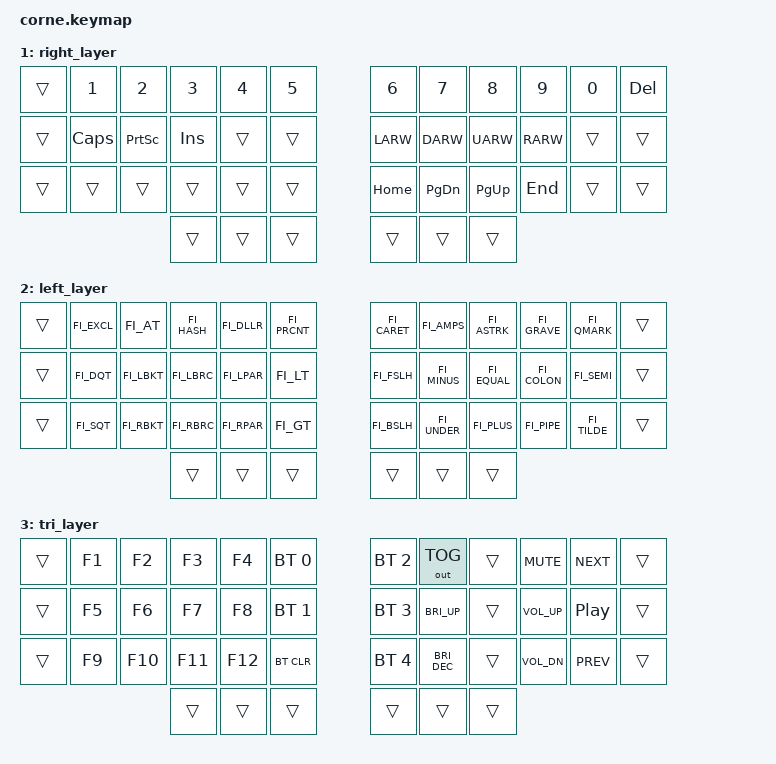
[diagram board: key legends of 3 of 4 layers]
#include <behaviors.dtsi>
#include <dt-bindings/zmk/keys.h>
#include <dt-bindings/zmk/bt.h>
#include <dt-bindings/zmk/outputs.h>
#include <locale/keys_fi.h>

// Home row mods
#define HRML(k2,k3,k4) &ht LALT k2  &ht LCTRL k3  &ht LGUI k4

// Right hand uses left-side modifier keycodes intentionally.
// On Nordic/Finnish layouts, RALT behaves as AltGr, so using LALT here
// gives normal Alt behavior on the physical right-hand home-row key.
#define HRMR(k1,k2,k3) &ht LGUI k1  &ht LCTRL k2  &ht LALT k3

#define DEF 0
#define RIG 1
#define LEF 2
#define TRI 3

/ {
    behaviors {
        ht: hold_tap {
            label = "hold_tap";
            compatible = "zmk,behavior-hold-tap";
            #binding-cells = <2>;
            flavor = "tap-preferred";
            tapping-term-ms = <220>;
            quick-tap-ms = <150>;
            global-quick-tap;
            bindings = <&kp>, <&kp>;
        };
    };

    conditional_layers {
        compatible = "zmk,conditional-layers";

        tri_layer {
            if-layers = <RIG LEF>;
            then-layer = <TRI>;
        };
    };

    keymap {
        compatible = "zmk,keymap";

        default_layer {
            bindings = <
        //╭──────────┬──────────┬──────────┬──────────┬──────────┬──────────╮   ╭──────────┬──────────┬──────────┬──────────┬──────────┬──────────╮
        //│  ESC     │  Q       │  W       │  E       │  R       │  T       │   │  Y       │  U       │  I       │  O       │  P       │ BACKSPC  │
            &kp ESC    &kp Q      &kp W      &kp E      &kp R      &kp T          &kp Y      &kp U      &kp I      &kp O      &kp P      &kp BSPC

        //├──────────┼──────────┼──────────┼──────────┼──────────┼──────────┤   ├──────────┼──────────┼──────────┼──────────┼──────────┼──────────┤
        //│  TAB     │  A       │  S/ALT   │  D/CTRL  │  F/GUI   │  G       │   │  H       │  J/GUI   │  K/CTRL  │  L/ALT   │  Ö       │  Ä       │
            &kp TAB    &kp A      HRML(S,      D,        F)        &kp G          &kp H      HRMR(J,      K,        L)        &kp FI_O_UMLAUT &kp FI_A_UMLAUT

        //├──────────┼──────────┼──────────┼──────────┼──────────┼──────────┤   ├──────────┼──────────┼──────────┼──────────┼──────────┼──────────┤
        //│  SHIFT   │  Z       │  X       │  C       │  V       │  B       │   │  N       │  M       │  ,       │  .       │  /       │          │
            &kp LSHIFT &kp Z      &kp X      &kp C      &kp V      &kp B          &kp N      &kp M      &kp FI_COMMA &kp FI_DOT &kp FI_FSLH &none

        //╰──────────┴──────────┴──────────┴──────────┼──────────┼──────────┤   ├──────────┼──────────┼──────────┴──────────┴──────────┴──────────╯
                                           &kp ESC    &lt LEF TAB &kp SPACE     &kp ENTER  &lt RIG TAB &kp LSHIFT
        //                                 ╰──────────┴──────────┴──────────╯   ╰──────────┴──────────┴──────────╯
            >;
        };

        right_layer {
            bindings = <
        //╭──────────┬──────────┬──────────┬──────────┬──────────┬──────────╮   ╭──────────┬──────────┬──────────┬──────────┬──────────┬──────────╮
        //│          │  1       │  2       │  3       │  4       │  5       │   │  6       │  7       │  8       │  9       │  0       │ DELETE   │
            &trans    &kp N1     &kp N2     &kp N3     &kp N4     &kp N5         &kp N6     &kp N7     &kp N8     &kp N9     &kp N0     &kp DEL

        //├──────────┼──────────┼──────────┼──────────┼──────────┼──────────┤   ├──────────┼──────────┼──────────┼──────────┼──────────┼──────────┤
        //│          │ CAPSLOCK │ PRINTSCR │ INSERT   │          │          │   │  LEFT    │  DOWN    │  UP      │  RIGHT   │          │          │
            &trans    &kp CAPS   &kp PSCRN  &kp INS    &trans     &trans         &kp LARW   &kp DARW   &kp UARW   &kp RARW   &trans     &trans

        //├──────────┼──────────┼──────────┼──────────┼──────────┼──────────┤   ├──────────┼──────────┼──────────┼──────────┼──────────┼──────────┤
        //│          │          │          │          │          │          │   │  HOME    │ PAGE DN  │ PAGE UP  │  END     │          │          │
            &trans    &trans     &trans     &trans     &trans     &trans         &kp HOME   &kp PG_DN  &kp PG_UP  &kp END    &trans     &trans

        //╰──────────┴──────────┴──────────┴──────────┼──────────┼──────────┤   ├──────────┼──────────┼──────────┴──────────┴──────────┴──────────╯
                                           &trans     &trans     &trans        &trans     &trans     &trans
        //                                 ╰──────────┴──────────┴──────────╯   ╰──────────┴──────────┴──────────╯
            >;
        };

        left_layer {
            bindings = <
        //╭──────────┬──────────┬──────────┬──────────┬──────────┬──────────╮   ╭──────────┬──────────┬──────────┬──────────┬──────────┬──────────╮
        //│          │  !       │  @       │  #       │  $       │  %       │   │  ^       │  &       │  *       │  `       │  ?       │          │
            &trans    &kp FI_EXCL &kp FI_AT   &kp FI_HASH &kp FI_DLLR &kp FI_PRCNT    &kp FI_CARET &kp FI_AMPS &kp FI_ASTRK &kp FI_GRAVE &kp FI_QMARK &trans
    
        //├──────────┼──────────┼──────────┼──────────┼──────────┼──────────┤   ├──────────┼──────────┼──────────┼──────────┼──────────┼──────────┤
        //│          │  "       │  [       │  {       │  (       │  <       │   │  /       │  -       │  =       │  :       │  ;       │          │
            &trans    &kp FI_DQT  &kp FI_LBKT &kp FI_LBRC &kp FI_LPAR &kp FI_LT       &kp FI_FSLH &kp FI_MINUS &kp FI_EQUAL &kp FI_COLON &kp FI_SEMI &trans
    
        //├──────────┼──────────┼──────────┼──────────┼──────────┼──────────┤   ├──────────┼──────────┼──────────┼──────────┼──────────┼──────────┤
        //│          │  '       │  ]       │  }       │  )       │  >       │   │  \       │  _       │  +       │  |       │  ~       │          │
            &trans    &kp FI_SQT  &kp FI_RBKT &kp FI_RBRC &kp FI_RPAR &kp FI_GT       &kp FI_BSLH &kp FI_UNDER &kp FI_PLUS &kp FI_PIPE &kp FI_TILDE &trans
    
        //╰──────────┴──────────┴──────────┴──────────┼──────────┼──────────┤   ├──────────┼──────────┼──────────┴──────────┴──────────┴──────────╯
                                           &trans     &trans     &trans        &trans     &trans     &trans
        //                                 ╰──────────┴──────────┴──────────╯   ╰──────────┴──────────┴──────────╯
            >;
        };

        tri_layer {
            bindings = <
        //╭──────────┬──────────┬──────────┬──────────┬────────────┬────────╮   ╭────────────┬────────────┬──────────┬───────────┬──────────┬──────────╮
        //│          │  F1      │  F2      │  F3      │  F4        │ BT 0   │   │ BT 2       │ OUT TOG    │          │ VOL MUTE  │ NEXT     │          │
            &trans    &kp F1     &kp F2     &kp F3     &kp F4       &bt BT_SEL 0   &bt BT_SEL 2  &out OUT_TOG &trans   &kp C_MUTE  &kp C_NEXT &trans

        //├──────────┼──────────┼──────────┼──────────┼────────────┼────────┤   ├────────────┼────────────┼──────────┼───────────┼──────────┼──────────┤
        //│          │  F5      │  F6      │  F7      │  F8        │ BT 1   │   │ BT 3       │ BRI UP     │          │ VOL UP    │ PLAY     │          │
            &trans    &kp F5     &kp F6     &kp F7     &kp F8       &bt BT_SEL 1   &bt BT_SEL 3  &kp C_BRI_UP &trans   &kp C_VOL_UP &kp C_PP   &trans

        //├──────────┼──────────┼──────────┼──────────┼────────────┼────────┤   ├────────────┼────────────┼──────────┼───────────┼──────────┼──────────┤
        //│          │  F9      │  F10     │  F11     │  F12       │ BT CLR │   │ BT 4       │ BRI DOWN   │          │ VOL DOWN  │ PREV     │          │
            &trans    &kp F9     &kp F10    &kp F11    &kp F12      &bt BT_CLR     &bt BT_SEL 4  &kp C_BRI_DEC &trans  &kp C_VOL_DN &kp C_PREV &trans

        //╰──────────┴──────────┴──────────┴──────────┼────────────┼────────┤   ├────────────┼────────────┼──────────┴───────────┴──────────┴──────────╯
                                           &trans     &trans       &trans       &trans       &trans       &trans
        //                                 ╰──────────┴────────────┴────────╯   ╰────────────┴────────────┴──────────╯
            >;
        };
    };
};
